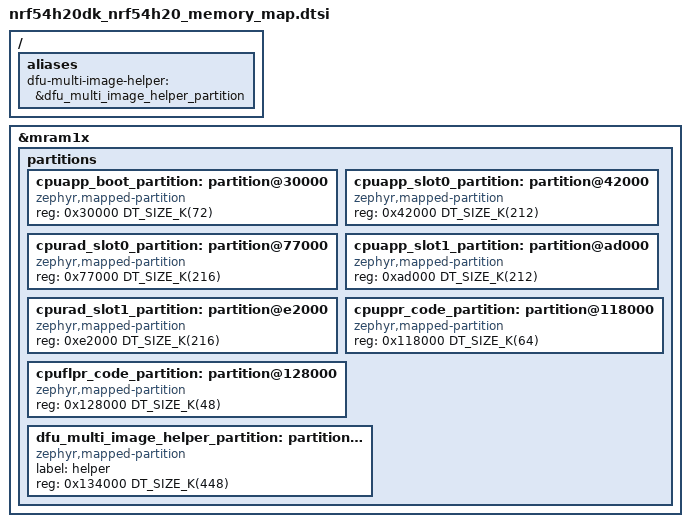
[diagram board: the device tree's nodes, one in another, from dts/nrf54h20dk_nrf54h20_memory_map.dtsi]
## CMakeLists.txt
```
#
# Copyright (c) 2025 Nordic Semiconductor ASA
#
# SPDX-License-Identifier: LicenseRef-Nordic-5-Clause
#

cmake_minimum_required(VERSION 3.20.0)

find_package(Zephyr REQUIRED HINTS $ENV{ZEPHYR_BASE})
project(dfu_multi_image)

target_sources(app PRIVATE src/main.c src/dfu_multi_image_shell.c)
```

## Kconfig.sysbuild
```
#
# Copyright (c) 2025 Nordic Semiconductor
#
# SPDX-License-Identifier: LicenseRef-Nordic-5-Clause
#

config SOC_SERIES_NRF53
	select MCUBOOT_NRF53_MULTI_IMAGE_UPDATE
	select SECURE_BOOT_NETCORE
	select NETCORE_APP_UPDATE

if SOC_SERIES_NRF53

choice MCUBOOT_MODE
	default MCUBOOT_MODE_OVERWRITE_ONLY
endchoice

endif # SOC_SERIES_NRF53

config PARTITION_MANAGER
	default n

source "${ZEPHYR_BASE}/share/sysbuild/Kconfig"
```

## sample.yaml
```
#
# Copyright (c) 2025 Nordic Semiconductor ASA
#
# SPDX-License-Identifier: LicenseRef-Nordic-5-Clause
#

sample:
  name: DFU multi-image sample
common:
  platform_allow:
    - nrf5340dk/nrf5340/cpuapp
    - nrf54h20dk/nrf54h20/cpuapp
  build_only: true
  sysbuild: true
tests:
  sample.dfu.dfu_multi_image:
    tags:
      - dfu_multi_image
      - ci_samples_dfu
    integration_platforms:
      - nrf5340dk/nrf5340/cpuapp
      - nrf54h20dk/nrf54h20/cpuapp
  sample.dfu.dfu_multi_image.save_progress:
    extra_configs:
      - CONFIG_DFU_TARGET_STREAM_SAVE_PROGRESS=y
      - CONFIG_DFU_MULTI_IMAGE_SAVE_PROGRESS=y
      - CONFIG_SETTINGS=y
      - CONFIG_NVS=y
    tags:
      - dfu_multi_image
      - ci_samples_dfu
    integration_platforms:
      - nrf5340dk/nrf5340/cpuapp
      - nrf54h20dk/nrf54h20/cpuapp
  sample.dfu.dfu_multi_image.encryption:
    extra_args:
      - SB_CONFIG_BOOT_ENCRYPTION=y
    tags:
      - dfu_multi_image
      - ci_samples_dfu
    integration_platforms:
      - nrf5340dk/nrf5340/cpuapp
      - nrf54h20dk/nrf54h20/cpuapp
```

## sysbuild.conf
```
#
# Copyright (c) 2025 Nordic Semiconductor ASA
#
# SPDX-License-Identifier: LicenseRef-Nordic-5-Clause
#

SB_CONFIG_BOOTLOADER_MCUBOOT=y
SB_CONFIG_DFU_MULTI_IMAGE_PACKAGE_BUILD=y
SB_CONFIG_DFU_MULTI_IMAGE_PACKAGE_APP=y
SB_CONFIG_DFU_MULTI_IMAGE_PACKAGE_NET=y

# Radio core build and update enable
SB_CONFIG_NETCORE_EMPTY=y
```

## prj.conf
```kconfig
#
# Copyright (c) 2025 Nordic Semiconductor ASA
#
# SPDX-License-Identifier: LicenseRef-Nordic-5-Clause
#

CONFIG_DFU_MULTI_IMAGE=y

# Enable DFU target mcuboot
CONFIG_DFU_TARGET=y
CONFIG_STREAM_FLASH=y
CONFIG_FLASH=y
CONFIG_FLASH_MAP=y
CONFIG_IMG_MANAGER=y

CONFIG_REBOOT=y

# Enable shell
CONFIG_SHELL=y
CONFIG_SHELL_BACKEND_SERIAL=y
CONFIG_LOG=y
```

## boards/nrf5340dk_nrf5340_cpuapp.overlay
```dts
/*
 * Copyright (c) 2026 Nordic Semiconductor ASA
 *
 * SPDX-License-Identifier: LicenseRef-Nordic-5-Clause
 */

/delete-node/ &boot_partition;
/delete-node/ &slot0_partition;
/delete-node/ &slot1_partition;
/delete-node/ &storage_partition;

/ {
	aliases {
		dfu-multi-image-helper = &dfu_multi_image_helper_partition;
	};
};

&flash0 {
	partitions {
		ranges;
		#address-cells = <1>;
		#size-cells = <1>;

		boot_partition: partition@0 {
			compatible = "zephyr,mapped-partition";
			label = "mcuboot";
			reg = <0x0 DT_SIZE_K(64)>;
		};

		slot0_partition: partition@10000 {
			compatible = "zephyr,mapped-partition";
			label = "image-0";
			reg = <0x10000 DT_SIZE_K(208)>;
		};

		slot1_partition: partition@44000 {
			compatible = "zephyr,mapped-partition";
			label = "image-1";
			reg = <0x44000 DT_SIZE_K(208)>;
		};

		/* 256 KB to match the default network-core primary slot (slot2/RAM flash). */
		slot3_partition: partition@78000 {
			compatible = "zephyr,mapped-partition";
			label = "image-3";
			reg = <0x78000 DT_SIZE_K(256)>;
		};

		dfu_multi_image_helper_partition: partition@b8000 {
			compatible = "zephyr,mapped-partition";
			label = "helper";
			reg = <0xb8000 DT_SIZE_K(256)>;
		};

		storage_partition: partition@f8000 {
			compatible = "zephyr,mapped-partition";
			label = "storage";
			reg = <0xf8000 DT_SIZE_K(32)>;
		};
	};
};
```

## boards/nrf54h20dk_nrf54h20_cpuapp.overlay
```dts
/*
 * Copyright (c) 2025 Nordic Semiconductor ASA
 *
 * SPDX-License-Identifier: LicenseRef-Nordic-5-Clause
 */

#include "../dts/nrf54h20dk_nrf54h20_memory_map.dtsi"

slot0_partition: &cpuapp_slot0_partition {
	label = "image-0";
};

slot1_partition: &cpuapp_slot1_partition {
	label = "image-1";
};

slot2_partition: &cpurad_slot0_partition {
	label = "image-2";
};

slot3_partition: &cpurad_slot1_partition {
	label = "image-3";
};
```

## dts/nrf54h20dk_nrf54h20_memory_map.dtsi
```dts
/*
 * Copyright (c) 2025 Nordic Semiconductor ASA
 *
 * SPDX-License-Identifier: LicenseRef-Nordic-5-Clause
 */

/delete-node/ &cpuapp_boot_partition;
/delete-node/ &cpuapp_slot0_partition;
/delete-node/ &cpuapp_slot1_partition;
/delete-node/ &cpurad_slot0_partition;
/delete-node/ &cpurad_slot1_partition;
/delete-node/ &cpuppr_code_partition;
/delete-node/ &cpuflpr_code_partition;

/ {
	aliases {
		dfu-multi-image-helper = &dfu_multi_image_helper_partition;
	};
};

&mram1x {
	partitions {
		cpuapp_boot_partition: partition@30000 {
			compatible = "zephyr,mapped-partition";
			reg = <0x30000 DT_SIZE_K(72)>;
		};

		cpuapp_slot0_partition: partition@42000 {
			compatible = "zephyr,mapped-partition";
			reg = <0x42000 DT_SIZE_K(212)>;
		};

		cpurad_slot0_partition: partition@77000 {
			compatible = "zephyr,mapped-partition";
			reg = <0x77000 DT_SIZE_K(216)>;
		};

		cpuapp_slot1_partition: partition@ad000 {
			compatible = "zephyr,mapped-partition";
			reg = <0xad000 DT_SIZE_K(212)>;
		};

		cpurad_slot1_partition: partition@e2000 {
			compatible = "zephyr,mapped-partition";
			reg = <0xe2000 DT_SIZE_K(216)>;
		};

		cpuppr_code_partition: partition@118000 {
			compatible = "zephyr,mapped-partition";
			reg = <0x118000 DT_SIZE_K(64)>;
		};

		cpuflpr_code_partition: partition@128000 {
			compatible = "zephyr,mapped-partition";
			reg = <0x128000 DT_SIZE_K(48)>;
		};

		dfu_multi_image_helper_partition: partition@134000 {
			compatible = "zephyr,mapped-partition";
			label = "helper";
			reg = <0x134000 DT_SIZE_K(448)>;
		};
	};
};
```

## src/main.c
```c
/*
 * Copyright (c) 2025 Nordic Semiconductor ASA
 *
 * SPDX-License-Identifier: LicenseRef-Nordic-5-Clause
 */

#include <stdio.h>
#include <stdint.h>
#include <dfu/dfu_multi_image.h>
#include <dfu/dfu_target.h>
#include <dfu/dfu_target_mcuboot.h>
#include <zephyr/dfu/mcuboot.h>
#if defined(CONFIG_SOC_NRF5340_CPUAPP)
#include <nrf53_cpunet_mgmt.h>
#endif

#include "dfu_multi_image_sample_common.h"

#include <zephyr/logging/log.h>

LOG_MODULE_REGISTER(dfu_multi_image_sample);

uint8_t dfu_multi_image_sample_buffer[DFU_MULTI_IMAGE_BUFFER_SIZE];

static void dfu_target_callback(enum dfu_target_evt_id evt_id)
{
	printf("DFU target event received: %d\n", evt_id);
}

static int writer_open(int image_id, size_t image_size)
{
	LOG_INF("Opening DFU target image %d with size %zu", image_id, image_size);
	return dfu_target_init(DFU_TARGET_IMAGE_TYPE_MCUBOOT, image_id, image_size,
			       dfu_target_callback);
}

static int writer_write(const uint8_t *chunk, size_t chunk_size)
{
	LOG_INF("Writing %zu bytes to DFU target image", chunk_size);
	return dfu_target_write(chunk, chunk_size);
}

static int writer_close(bool success)
{
	LOG_INF("Closing DFU target image %s", success ? "successfully" : "with failure");
	return dfu_target_done(success);
}

#ifdef CONFIG_DFU_MULTI_IMAGE_SAVE_PROGRESS
static int writer_offset(size_t *offset)
{
	return dfu_target_offset_get(offset);
}
#endif

static int writer_reset(void)
{
	LOG_INF("Resetting DFU target image");
	return dfu_target_reset();
}

int dfu_multi_image_sample_lib_prepare(void)
{
	int ret = 0;

	ret = dfu_target_mcuboot_set_buf(dfu_multi_image_sample_buffer,
					 DFU_MULTI_IMAGE_BUFFER_SIZE);

	if (ret < 0) {
		LOG_ERR("Failed to set buffer for MCUboot DFU target: %d", ret);
		return ret;
	}

	ret = dfu_multi_image_init(dfu_multi_image_sample_buffer, DFU_MULTI_IMAGE_BUFFER_SIZE);

	if (ret < 0) {
		LOG_ERR("Failed to initialize dfu_multi_image: %d", ret);
		return ret;
	}

	for (int image_id = 0; image_id < CONFIG_UPDATEABLE_IMAGE_NUMBER; ++image_id) {
		struct dfu_image_writer writer;

		writer.image_id = image_id;
		writer.open = writer_open;
		writer.write = writer_write;
		writer.close = writer_close;
#ifdef CONFIG_DFU_MULTI_IMAGE_SAVE_PROGRESS
		writer.offset = writer_offset;
#endif /* CONFIG_DFU_MULTI_IMAGE_SAVE_PROGRESS */
		writer.reset = writer_reset;

		ret = dfu_multi_image_register_writer(&writer);
		if (ret < 0) {
			LOG_ERR("Failed to register writer for image %d: %d", image_id, ret);
			return ret;
		}
	};

	return 0;
}

int main(void)
{
	int ret = 0;

#if defined(CONFIG_SOC_NRF5340_CPUAPP)
	nrf53_cpunet_enable(true);
#endif

	ret = dfu_multi_image_sample_lib_prepare();

	if (ret < 0) {
		printf("Failed to prepare dfu_multi_image sample: %d\n", ret);
		return ret;
	}
	/* using __TIME__ ensure that a new binary will be built on every
	 * compile which is convenient when testing firmware upgrade.
	 */
	printf("Starting dfu_multi_image sample, build time: %s %s\n", __DATE__, __TIME__);

	return 0;
}
```

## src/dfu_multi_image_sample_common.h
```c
/*
 * Copyright (c) 2025 Nordic Semiconductor ASA
 *
 * SPDX-License-Identifier: LicenseRef-Nordic-5-Clause
 */

#ifndef DFU_MULTI_IMAGE_SAMPLE_COMMON_H__
#define DFU_MULTI_IMAGE_SAMPLE_COMMON_H__

#include <stdint.h>

#define DFU_MULTI_IMAGE_BUFFER_SIZE 1024
extern uint8_t dfu_multi_image_sample_buffer[DFU_MULTI_IMAGE_BUFFER_SIZE];

/**
 * @brief Prepare the dfu_multi_image library for operation with the
 *        sample.
 */
int dfu_multi_image_sample_lib_prepare(void);

#endif /* DFU_MULTI_IMAGE_SAMPLE_COMMON_H__ */
```

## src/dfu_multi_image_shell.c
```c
/*
 * Copyright (c) 2025 Nordic Semiconductor ASA
 *
 * SPDX-License-Identifier: LicenseRef-Nordic-5-Clause
 */

#include <stdio.h>
#include <stdlib.h>

#include <zephyr/shell/shell.h>
#include <zephyr/sys/reboot.h>
#include <dfu/dfu_target.h>
#include <dfu/dfu_multi_image.h>
#include <zephyr/dfu/mcuboot.h>

#include "dfu_multi_image_sample_common.h"

#define DFU_MULTI_IMAGE_HELPER_ADDRESS ((uint32_t)DT_REG_ADDR(DT_ALIAS(dfu_multi_image_helper)))
#define DFU_MULTI_IMAGE_HELPER_SIZE    DT_REG_SIZE(DT_ALIAS(dfu_multi_image_helper))

static int cmd_dfu_multi_image_write(const struct shell *shell, size_t argc, char **argv)
{
	int ret = 0;
	int read_offset;
	int write_offset;
	int chunk_size;

	if (argc != 4) {
		shell_error(shell, "Usage: dfu_multi_image write <read_offset> <write_offset> "
				   "<chunk_size>");
		return -EINVAL;
	}

	read_offset = shell_strtol(argv[1], 10, &ret);
	if (ret != 0) {
		shell_error(shell, "Invalid <read_offset> argument");
		return -EINVAL;
	}
	write_offset = shell_strtol(argv[2], 10, &ret);
	if (ret != 0) {
		shell_error(shell, "Invalid <write_offset> argument");
		return -EINVAL;
	}
	chunk_size = shell_strtol(argv[3], 10, &ret);
	if (ret != 0) {
		shell_error(shell, "Invalid <chunk_size> argument");
		return -EINVAL;
	}

	if (read_offset < 0 || write_offset < 0 || chunk_size <= 0) {
		shell_error(shell,
			    "Invalid arguments: offsets must be >= 0 and chunk_size must be > 0");
		return -EINVAL;
	}

	ret = dfu_multi_image_write(write_offset,
				    (const void *const) (DFU_MULTI_IMAGE_HELPER_ADDRESS
							 + read_offset),
				    chunk_size);
	if (ret < 0) {
		shell_error(shell, "DFU multi image write failed: %d", ret);
		return ret;
	} else {
		shell_print(shell, "Successfully wrote %d bytes at offset %d", chunk_size,
			    write_offset);
	}

	return 0;
}

static int cmd_dfu_multi_image_offset_get(const struct shell *shell, size_t argc, char **argv)
{
	shell_print(shell, "%zu", dfu_multi_image_offset());

	return 0;
}

static int cmd_dfu_multi_image_done(const struct shell *shell, size_t argc, char **argv)
{
	int ret = 0;
	bool successful = false;

	if (argc != 2) {
		shell_error(shell, "Invalid number of arguments. "
					       "Usage: dfu_multi_image done <success|fail>");
		return -EINVAL;
	}

	if (strcmp(argv[1], "success") == 0) {
		successful = true;
	} else if (strcmp(argv[1], "fail") == 0) {
		successful = false;
	} else {
		shell_error(shell, "Invalid argument. Usage: dfu_multi_image done <success|fail>");
		return -EINVAL;
	}

	ret = dfu_multi_image_done(successful);
	if (ret < 0) {
		shell_error(shell, "DFU multi image done failed: %d", ret);
		return ret;
	}

	return 0;
}

static int cmd_dfu_multi_image_schedule_update(const struct shell *shell, size_t argc, char **argv)
{
	int ret = 0;

	ret = dfu_target_schedule_update(-1);
	if (ret < 0) {
		shell_error(shell, "DFU target schedule update failed: %d", ret);
		return ret;
	}

	return 0;
}

static int cmd_dfu_multi_image_reset(const struct shell *shell, size_t argc, char **argv)
{
	int ret = 0;

	ret = dfu_multi_image_reset();
	if (ret < 0) {
		shell_error(shell, "DFU multi image reset failed: %d", ret);
		return ret;
	}

	ret = dfu_multi_image_sample_lib_prepare();

	if (ret < 0) {
		shell_error(shell, "Failed to prepare dfu_multi_image library: %d", ret);
		return ret;
	}

	return 0;
}

static int cmd_dfu_multi_image_full_update(const struct shell *shell, size_t argc, char **argv)
{
	int ret = 0;
	int package_size;

	if (argc != 2) {
		shell_error(shell, "Usage: dfu_multi_image full_update <package_size>");
		return -EINVAL;
	}

	package_size = shell_strtol(argv[1], 10, &ret);
	if (ret != 0) {
		shell_error(shell, "Invalid <package_size> argument");
		return -EINVAL;
	}

	if (package_size <= 0) {
		shell_error(shell, "Invalid arguments: package_size must be > 0");
		return -EINVAL;
	}

	ret = dfu_multi_image_write(0, (const void *const) (DFU_MULTI_IMAGE_HELPER_ADDRESS),
				    package_size);
	if (ret < 0) {
		shell_error(shell, "DFU multi image write failed: %d", ret);
		return ret;
	}

	ret = dfu_multi_image_done(true);
	if (ret < 0) {
		shell_error(shell, "DFU multi image done failed: %d", ret);
		return ret;
	}

	ret = dfu_target_schedule_update(-1);
	if (ret < 0) {
		shell_error(shell, "Failed to schedule update: %d", ret);
		return ret;
	}

	sys_reboot(SYS_REBOOT_COLD);

	return 0;
}

#ifndef CONFIG_MCUBOOT_IMGTOOL_OVERWRITE_ONLY
static int cmd_dfu_multi_image_mcuboot_confirm(const struct shell *shell, size_t argc, char **argv)
{
	int ret = 0;
	int img_num = -1;

	if (argc != 2) {
		shell_error(shell, "Usage: dfu_multi_image mcuboot_confirm <img_num>");
		return -EINVAL;
	}

	img_num = shell_strtol(argv[1], 10, &ret);
	if (ret != 0) {
		shell_error(shell, "Invalid <img_num> argument");
		return -EINVAL;
	}
	ret = boot_write_img_confirmed_multi(img_num);

	if (ret < 0) {
		shell_error(shell, "Failed to confirm current MCUBOOT image: %d", ret);
		return ret;
	}

	return 0;
}
#endif

/* Define the dfu_target subcommand group */
SHELL_STATIC_SUBCMD_SET_CREATE(dfu_multi_image_cmds,
	SHELL_CMD(write, NULL,
		  "Write a chunk of data at a given offset inside the buffer in NVM "
		  "into dfu_multi_image",
		  cmd_dfu_multi_image_write),
	SHELL_CMD(offset_get, NULL, "Retrieve the current write offset of dfu_multi_image",
		  cmd_dfu_multi_image_offset_get),
	SHELL_CMD(done, NULL, "Done writing data", cmd_dfu_multi_image_done),
	SHELL_CMD(schedule_update, NULL, "Schedule update for the images in the uploaded package.",
		  cmd_dfu_multi_image_schedule_update),
	SHELL_CMD(reset, NULL, "Reset the dfu_multi_image state as well as all the underlying "
		  "dfu_target states", cmd_dfu_multi_image_reset),
	SHELL_CMD(full_update, NULL,
		  "Perform all the steps to fully update the firmware from the NVM buffer",
		  cmd_dfu_multi_image_full_update),
#ifndef CONFIG_MCUBOOT_IMGTOOL_OVERWRITE_ONLY
	SHELL_CMD(mcuboot_confirm, NULL, "Confirm one of the current MCUBOOT images",
		  cmd_dfu_multi_image_mcuboot_confirm),
#endif
	SHELL_SUBCMD_SET_END
);

/* Register the dfu_target command group */
SHELL_CMD_REGISTER(dfu_multi_image, &dfu_multi_image_cmds, "DFU multi_image commands", NULL);
```
